# FM33FH0XX register map
File version: 1.0
CPU: SC000 r1p0, little endian, no MPU, no FPU, 3 interrupt priority bits
Registers are 32-bit, read-write, reset 0x0 unless marked. A register's access mark holds for its fields unless they carry their own. Offsets are from the block's base; [hi:lo] are bit positions.

## TSI — TSI module information
Base 0x40010000
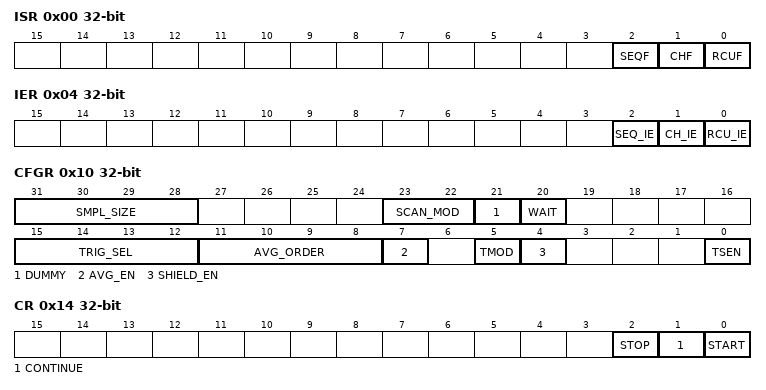
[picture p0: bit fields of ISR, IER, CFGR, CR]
0x00 ISR
  [2] SEQF — SEQF field description
  [1] CHF — CHF field description
  [0] RCUF — RCUF field description
0x04 IER
  [2] SEQ_IE — SEQ_IE field description
  [1] CH_IE — CH_IE field description
  [0] RCU_IE — RCU_IE field description
0x08 RXSR
  [5:0] RXSR ro — RXSR field description
0x0C TXSR
  [5:0] TXSR ro — TXSR field description
0x10 CFGR
  [31:28] SMPL_SIZE — SMPL_SIZE field description
  [23:22] SCAN_MOD — SCAN_MOD field description
  [21] DUMMY — DUMMY field description
  [20] WAIT — WAIT field description
  [15:12] TRIG_SEL — TRIG_SEL field description
  [11:8] AVG_ORDER — AVG_ORDER field description
  [7] AVG_EN — AVG_EN field description
  [5] TMOD — TMOD field description
  [4] SHIELD_EN — SHIELD_EN field description
  [0] TSEN — TSEN field description
0x14 CR
  [2] STOP wo — STOP field description
  [1] CONTINUE wo — CONTINUE field description
  [0] START — START field description
0x18 CHCR0
  [31:0] CHEN — CHEN field description
0x1C CHCR1
  [3:0] CHEN1 — CHEN1 field description
0x20 CHCFGR0
  [31:0] CHCFG — CHCFG field description
0x24 CHCFGR1
  [3:0] CHCFG — CHCFG field description
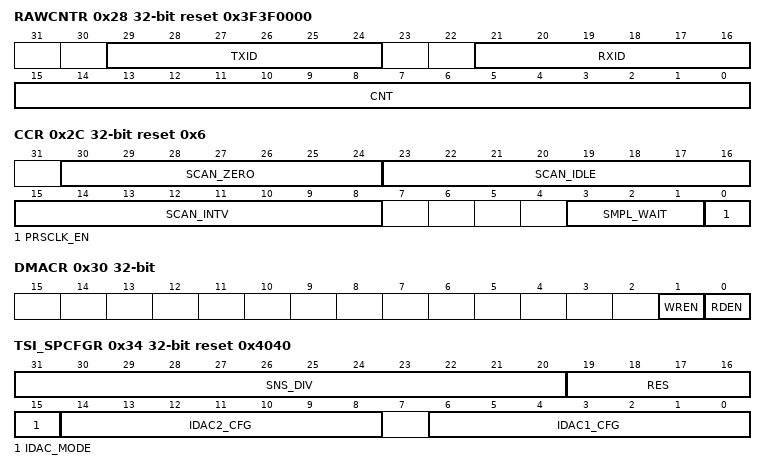
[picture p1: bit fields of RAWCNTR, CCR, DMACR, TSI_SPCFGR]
0x28 RAWCNTR reset 0x3F3F0000
  [29:24] TXID ro — TXID field description
  [21:16] RXID ro — RXID field description
  [15:0] CNT ro — CNT field description
0x2C CCR reset 0x6
  [30:24] SCAN_ZERO — SCAN_ZERO field description
  [23:16] SCAN_IDLE — SCAN_IDLE field description
  [15:8] SCAN_INTV — SCAN_INTV field description
  [3:1] SMPL_WAIT — SMPL_WAIT field description
  [0] PRSCLK_EN — PRSCLK_EN field description
0x30 DMACR
  [1] WREN — WREN field description
  [0] RDEN — RDEN field description
0x34 TSI_SPCFGR reset 0x4040
  [31:20] SNS_DIV — SNS_DIV field description
  [19:16] RES — RES field description
  [15] IDAC_MODE — IDAC_MODE field description
  [14:8] IDAC2_CFG — IDAC2_CFG field description
  [6:0] IDAC1_CFG — IDAC1_CFG field description
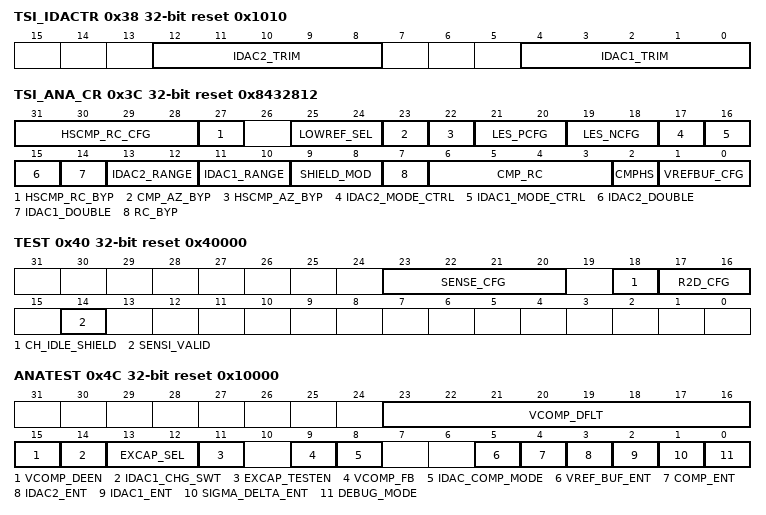
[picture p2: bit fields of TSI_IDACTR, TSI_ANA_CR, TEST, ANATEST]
0x38 TSI_IDACTR reset 0x1010
  [12:8] IDAC2_TRIM — IDAC2_TRIM field description
  [4:0] IDAC1_TRIM — IDAC1_TRIM field description
0x3C TSI_ANA_CR reset 0x8432812
  [31:28] HSCMP_RC_CFG — HSCMP_RC_CFG field description
  [27] HSCMP_RC_BYP — HSCMP_RC_BYP field description
  [25:24] LOWREF_SEL — LOWREF_SEL field description
  [23] CMP_AZ_BYP — CMP_AZ_BYP field description
  [22] HSCMP_AZ_BYP — HSCMP_AZ_BYP field description
  [21:20] LES_PCFG — LES_PCFG field description
  [19:18] LES_NCFG — LES_NCFG field description
  [17] IDAC2_MODE_CTRL — IDAC2_MODE_CTRL field description
  [16] IDAC1_MODE_CTRL — IDAC1_MODE_CTRL field description
  [15] IDAC2_DOUBLE — IDAC2_DOUBLE field description
  [14] IDAC1_DOUBLE — IDAC1_DOUBLE field description
  [13:12] IDAC2_RANGE — IDAC2_RANGE field description
  [11:10] IDAC1_RANGE — IDAC1_RANGE field description
  [9:8] SHIELD_MOD — SHIELD_MOD field description
  [7] RC_BYP — RC_BYP field description
  [6:3] CMP_RC — CMP_RC field description
  [2] CMPHS — CMPHS field description
  [1:0] VREFBUF_CFG — VREFBUF_CFG field description
0x40 TEST reset 0x40000
  [23:20] SENSE_CFG — SENSE_CFG field description
  [18] CH_IDLE_SHIELD — CH_IDLE_SHIELD field description
  [17:16] R2D_CFG — R2D_CFG field description
  [14] SENSI_VALID — SENSI_VALID field description
0x44 TESTRING0
  [31:0] EN — EN field description
0x48 TESTRING1
  [3:0] EN — EN field description
0x4C ANATEST reset 0x10000
  [23:16] VCOMP_DFLT — VCOMP_DFLT field description
  [15] VCOMP_DEEN — VCOMP_DEEN field description
  [14] IDAC1_CHG_SWT — IDAC1_CHG_SWT field description
  [13:12] EXCAP_SEL — EXCAP_SEL field description
  [11] EXCAP_TESTEN — EXCAP_TESTEN field description
  [9] VCOMP_FB — VCOMP_FB field description
  [8] IDAC_COMP_MODE — IDAC_COMP_MODE field description
  [5] VREF_BUF_ENT — VREF_BUF_ENT field description
  [4] COMP_ENT — COMP_ENT field description
  [3] IDAC2_ENT — IDAC2_ENT field description
  [2] IDAC1_ENT — IDAC1_ENT field description
  [1] SIGMA_DELTA_ENT — SIGMA_DELTA_ENT field description
  [0] DEBUG_MODE — DEBUG_MODE field description
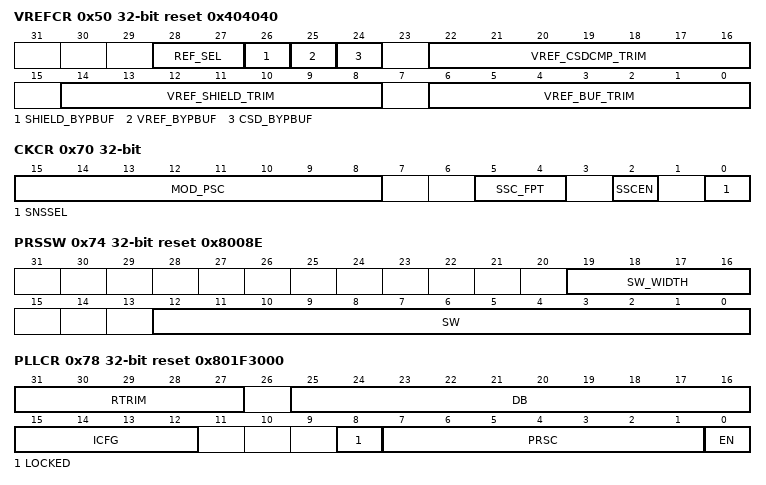
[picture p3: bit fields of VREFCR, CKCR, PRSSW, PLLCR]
0x50 VREFCR reset 0x404040
  [28:27] REF_SEL — REF_SEL field description
  [26] SHIELD_BYPBUF — SHIELD_BYPBUF field description
  [25] VREF_BYPBUF — VREF_BYPBUF field description
  [24] CSD_BYPBUF — CSD_BYPBUF field description
  [22:16] VREF_CSDCMP_TRIM — VREF_CSDCMP_TRIM field description
  [14:8] VREF_SHIELD_TRIM — VREF_SHIELD_TRIM field description
  [6:0] VREF_BUF_TRIM — VREF_BUF_TRIM field description
0x58 SHLDGNDCR0
  [31:0] EN — EN field description
0x5C TSHLDGNDCR1
  [3:0] EN — EN field description
0x60 EMICR0
  [31:0] SR_CFG1 — SR_CFG1 field description
0x64 EMICR1
  [31:0] SR_CFG — SR_CFG field description
0x68 SHLDCR0
  [31:0] EN — EN field description
0x6C SHLDCR1
  [3:0] EN — EN field description
0x70 CKCR
  [15:8] MOD_PSC — MOD_PSC field description
  [5:4] SSC_FPT — SSC_FPT field description
  [2] SSCEN — SSCEN field description
  [0] SNSSEL — SNSSEL field description
0x74 PRSSW reset 0x8008E
  [19:16] SW_WIDTH — SW_WIDTH field description
  [12:0] SW — SW field description
0x78 PLLCR reset 0x801F3000
  [31:27] RTRIM — RTRIM field description
  [25:16] DB — DB field description
  [15:12] ICFG — ICFG field description
  [8] LOCKED ro — LOCKED field description
  [7:1] PRSC — PRSC field description
  [0] EN — EN field description
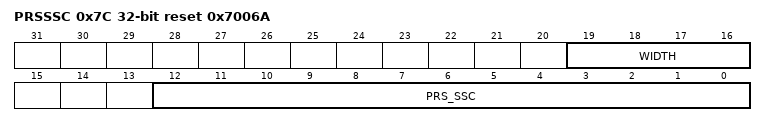
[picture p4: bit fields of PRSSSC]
0x7C PRSSSC reset 0x7006A
  [19:16] WIDTH — WIDTH field description
  [12:0] PRS_SSC — PRS_SSC field description
